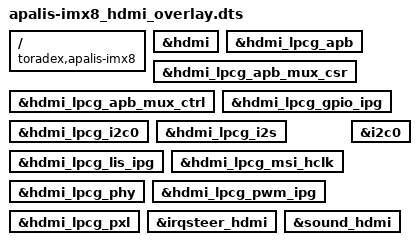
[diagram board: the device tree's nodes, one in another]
// SPDX-License-Identifier: GPL-2.0-or-later OR MIT
/*
 * Copyright 2020-2021 Toradex
 */

// Enable a generic HDMI interface.

/dts-v1/;
/plugin/;
/ {
	compatible = "toradex,apalis-imx8";
};

/* Apalis HDMI1 */
&hdmi {
	status = "okay";
};

&hdmi_lpcg_apb {
	status = "okay";
};

&hdmi_lpcg_apb_mux_csr {
	status = "okay";
};

&hdmi_lpcg_apb_mux_ctrl {
	status = "okay";
};

&hdmi_lpcg_gpio_ipg {
	status = "okay";
};

&hdmi_lpcg_i2c0 {
	status = "okay";
};

&hdmi_lpcg_i2s {
	status = "okay";
};

&hdmi_lpcg_lis_ipg {
	status = "okay";
};

&hdmi_lpcg_msi_hclk {
	status = "okay";
};

&hdmi_lpcg_phy {
	status = "okay";
};

&hdmi_lpcg_pwm_ipg {
	status = "okay";
};

&hdmi_lpcg_pxl {
	status = "okay";
};

/* Apalis I2C2 (DDC) */
&i2c0 {
	status = "okay";
};

&irqsteer_hdmi {
	status = "okay";
};

&sound_hdmi {
	status = "okay";
};
